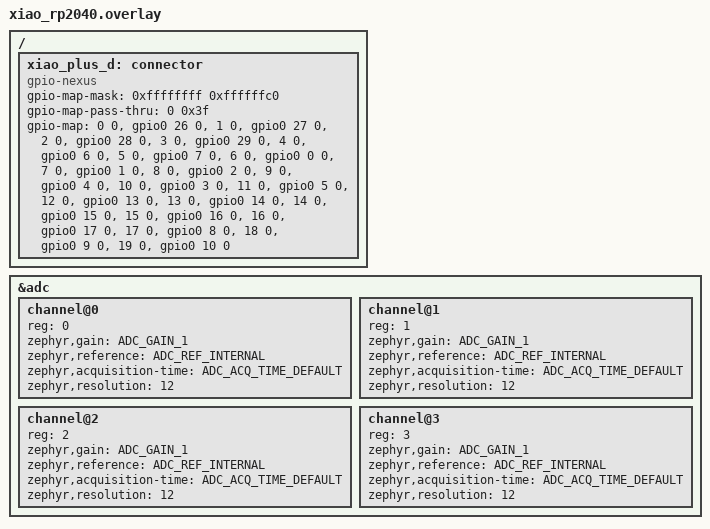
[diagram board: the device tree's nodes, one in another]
#include "rp2040_storage_partition.dtsi"
#include "rp2040_xosc_startup_delay.dtsi"

xiao_adc: &adc {
    #address-cells = <1>;
    #size-cells = <0>;

    channel@0 {
        reg = <0>; /* D0, GPIO26 */
        zephyr,gain = "ADC_GAIN_1";
        zephyr,reference = "ADC_REF_INTERNAL";
        zephyr,acquisition-time = <ADC_ACQ_TIME_DEFAULT>;
        zephyr,resolution = <12>;
    };

    channel@1 {
        reg = <1>; /* D1, GPIO27 */
        zephyr,gain = "ADC_GAIN_1";
        zephyr,reference = "ADC_REF_INTERNAL";
        zephyr,acquisition-time = <ADC_ACQ_TIME_DEFAULT>;
        zephyr,resolution = <12>;
    };

    channel@2 {
        reg = <2>; /* D2, GPIO28 */
        zephyr,gain = "ADC_GAIN_1";
        zephyr,reference = "ADC_REF_INTERNAL";
        zephyr,acquisition-time = <ADC_ACQ_TIME_DEFAULT>;
        zephyr,resolution = <12>;
    };

    channel@3 {
        reg = <3>; /* D3, GPIO29 */
        zephyr,gain = "ADC_GAIN_1";
        zephyr,reference = "ADC_REF_INTERNAL";
        zephyr,acquisition-time = <ADC_ACQ_TIME_DEFAULT>;
        zephyr,resolution = <12>;
    };
};

/ {
    xiao_plus_d: connector {
        compatible = "gpio-nexus";
        #gpio-cells = <2>;
        gpio-map-mask = <0xffffffff 0xffffffc0>;
        gpio-map-pass-thru = <0 0x3f>;
        gpio-map = <0 0 &gpio0 26 0>, /* D0 */
            <1 0 &gpio0 27 0>,       /* D1 */
            <2 0 &gpio0 28 0>,       /* D2 */
            <3 0 &gpio0 29 0>,       /* D3 */
            <4 0 &gpio0 6 0>,        /* D4 */
            <5 0 &gpio0 7 0>,        /* D5 */
            <6 0 &gpio0 0 0>,        /* D6 */
            <7 0 &gpio0 1 0>,        /* D7 */
            <8 0 &gpio0 2 0>,        /* D8 */
            <9 0 &gpio0 4 0>,        /* D9 */
            <10 0 &gpio0 3 0>,       /* D10 */
            <11 0 &gpio0 5 0>,       /* D0.5 */
            <12 0 &gpio0 13 0>,      /* D1.5 */
            <13 0 &gpio0 14 0>,      /* D2.5 */
            <14 0 &gpio0 15 0>,      /* D3.5 */
            <15 0 &gpio0 16 0>,      /* D4.5 */
            <16 0 &gpio0 17 0>,      /* D5.5 */
            <17 0 &gpio0 8 0>,       /* D7.5 */
            <18 0 &gpio0 9 0>,       /* D8.5 */
            <19 0 &gpio0 10 0>;      /* D9.5 */
    };
};
